AUTOSAR XML (schema 4-2-1)
package /ComponentTypes
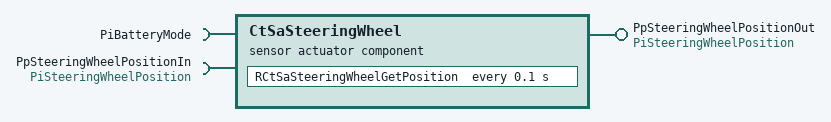
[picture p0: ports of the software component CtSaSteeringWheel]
  sensor actuator sw component type CtSaSteeringWheel
    provide port PpSteeringWheelPositionOut: nonqueued-sender-com-spec{data-element=DeSteeringWheelPosition, init-value=0}, provided-interface=PiSteeringWheelPosition
    require port PiBatteryMode: required-interface=PiBatteryMode
    require port PpSteeringWheelPositionIn: nonqueued-receiver-com-spec{data-element=DeSteeringWheelPosition, filter=data-filter-type=ALWAYS, init-value=constant-reference=CSteeringWheelInitPosition}, required-interface=PiSteeringWheelPosition
    behavior CtSaSteeringWheel_InternalBehavior
      timing event TMT_RCtSaSteeringWheelGetPosition: start-on-event=RCtSaSteeringWheelGetPosition, period=0.1
      runnable RCtSaSteeringWheelGetPosition: mode-access-point=PiBatteryMode.BatteryMode
        data-receive-point-by-arguments:
          access REC_PpSteeringWheelPosition_DeSteeringWheelPosition: accessed-variable=PpSteeringWheelPositionIn.DeSteeringWheelPosition
        data-send-points:
          access SEND_PpSteeringWheelPositionOut_DeSteeringWheelPosition: accessed-variable=PpSteeringWheelPositionOut.DeSteeringWheelPosition
  swc implementation CtSaSteeringWheel_Implementation: behavior=CtSaSteeringWheel_InternalBehavior
    code-descriptors:
      code Default: artifact-descriptors=autosar-engineering-object={short-label=Default, category=SWSRC}
